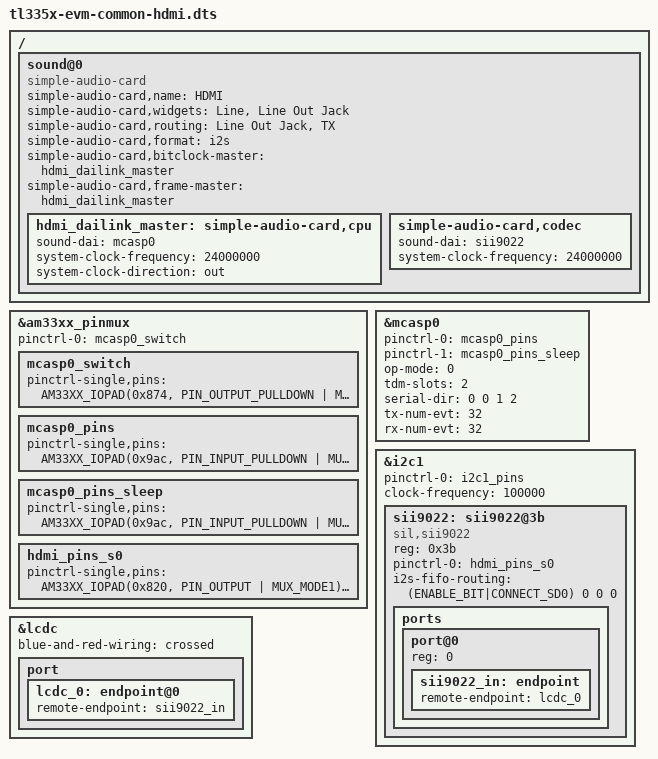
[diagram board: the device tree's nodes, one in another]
/*
 * Copyright (C) 2015 GuangZhou Tronlong co., LTD - http://www.tronlong.com
 *
 * This program is free software; you can redistribute it and/or modify
 * it under the terms of the GNU General Public License version 2 as
 * published by the Free Software Foundation.
 */

#include <dt-bindings/sound/sii9022-audio.h>
#include "tl335x-evm-common.dts"

/ {
	sound@0 {
		compatible = "simple-audio-card";
		simple-audio-card,name = "HDMI";
		simple-audio-card,widgets =
			"Line", "Line Out Jack";

		simple-audio-card,routing =
			"Line Out Jack", "TX";

		simple-audio-card,format = "i2s";
		simple-audio-card,bitclock-master = <&hdmi_dailink_master>;
		simple-audio-card,frame-master = <&hdmi_dailink_master>;
		hdmi_dailink_master: simple-audio-card,cpu {
			sound-dai = <&mcasp0>;
			/*
			* 22579200
			*/
			system-clock-frequency = <24000000>;
			system-clock-direction = "out";
		};

		simple-audio-card,codec {
			sound-dai = <&sii9022>;
			system-clock-frequency = <24000000>;
		};
	};
};

&am33xx_pinmux {
	pinctrl-0 = <&mcasp0_switch>;

	/*
	* switcher for mcasp0 signal
	* when this pin set to 0, mcasp0 signal switch to hdmi channel
	* when this pin set to 1, mcasp0 signal switch to tl3106h module
	*/
	mcasp0_switch: mcasp0_switch {
		pinctrl-single,pins = <
			AM33XX_IOPAD(0x874, PIN_OUTPUT_PULLDOWN | MUX_MODE7)	/* (U17) GPMC_WPN/GPIO0[31] */
		>;
	};

	mcasp0_pins: mcasp0_pins {
		pinctrl-single,pins = <
			AM33XX_IOPAD(0x9ac, PIN_INPUT_PULLDOWN | MUX_MODE0)	/* (A14) MCASP0_AHCLKX.MCASP0_AHCLKX */
			AM33XX_IOPAD(0x990, PIN_INPUT_PULLDOWN | MUX_MODE0)	/* (A13) MCASP0_ACLKX.MCASP0_ACLKX */
			AM33XX_IOPAD(0x994, PIN_INPUT_PULLDOWN | MUX_MODE0)	/* (B13) MCASP0_FSX.MCASP0_FSX */
			AM33XX_IOPAD(0x9a0, PIN_OUTPUT_PULLDOWN | MUX_MODE2)	/* (B12) MCASP0_ACLKR.MCASP0_AXR2 */
			AM33XX_IOPAD(0x9a4, PIN_INPUT_PULLDOWN | MUX_MODE2)	/* (C13) MCASP0_FSR.MCASP0_AXR3 */
		>;
	};

	mcasp0_pins_sleep: mcasp0_pins_sleep {
		pinctrl-single,pins = <
			AM33XX_IOPAD(0x9ac, PIN_INPUT_PULLDOWN | MUX_MODE7)
			AM33XX_IOPAD(0x990, PIN_INPUT_PULLDOWN | MUX_MODE7)
			AM33XX_IOPAD(0x994, PIN_INPUT_PULLDOWN | MUX_MODE7)
			AM33XX_IOPAD(0x9a0, PIN_INPUT_PULLDOWN | MUX_MODE7)
			AM33XX_IOPAD(0x9a4, PIN_INPUT_PULLDOWN | MUX_MODE7)
		>;
	};

	hdmi_pins_s0: hdmi_pins_s0 {
		pinctrl-single,pins = <
			AM33XX_IOPAD(0x820, PIN_OUTPUT | MUX_MODE1)		/* gpmc_ad8.lcd_data23 */
			AM33XX_IOPAD(0x824, PIN_OUTPUT | MUX_MODE1)		/* gpmc_ad9.lcd_data22 */
			AM33XX_IOPAD(0x828, PIN_OUTPUT | MUX_MODE1)		/* gpmc_ad10.lcd_data21 */
			AM33XX_IOPAD(0x82c, PIN_OUTPUT | MUX_MODE1)		/* gpmc_ad11.lcd_data20 */
			AM33XX_IOPAD(0x830, PIN_OUTPUT | MUX_MODE1)		/* gpmc_ad12.lcd_data19 */
			AM33XX_IOPAD(0x834, PIN_OUTPUT | MUX_MODE1)		/* gpmc_ad13.lcd_data18 */
			AM33XX_IOPAD(0x838, PIN_OUTPUT | MUX_MODE1)		/* gpmc_ad14.lcd_data17 */
			AM33XX_IOPAD(0x83c, PIN_OUTPUT | MUX_MODE1)		/* gpmc_ad15.lcd_data16 */
			AM33XX_IOPAD(0x8a0, PIN_OUTPUT | MUX_MODE0)		/* lcd_data0.lcd_data0 */
			AM33XX_IOPAD(0x8a4, PIN_OUTPUT | MUX_MODE0)		/* lcd_data1.lcd_data1 */
			AM33XX_IOPAD(0x8a8, PIN_OUTPUT | MUX_MODE0)		/* lcd_data2.lcd_data2 */
			AM33XX_IOPAD(0x8ac, PIN_OUTPUT | MUX_MODE0)		/* lcd_data3.lcd_data3 */
			AM33XX_IOPAD(0x8b0, PIN_OUTPUT | MUX_MODE0)		/* lcd_data4.lcd_data4 */
			AM33XX_IOPAD(0x8b4, PIN_OUTPUT | MUX_MODE0)		/* lcd_data5.lcd_data5 */
			AM33XX_IOPAD(0x8b8, PIN_OUTPUT | MUX_MODE0)		/* lcd_data6.lcd_data6 */
			AM33XX_IOPAD(0x8bc, PIN_OUTPUT | MUX_MODE0)		/* lcd_data7.lcd_data7 */
			AM33XX_IOPAD(0x8c0, PIN_OUTPUT | MUX_MODE0)		/* lcd_data8.lcd_data8 */
			AM33XX_IOPAD(0x8c4, PIN_OUTPUT | MUX_MODE0)		/* lcd_data9.lcd_data9 */
			AM33XX_IOPAD(0x8c8, PIN_OUTPUT | MUX_MODE0)		/* lcd_data10.lcd_data10 */
			AM33XX_IOPAD(0x8cc, PIN_OUTPUT | MUX_MODE0)		/* lcd_data11.lcd_data11 */
			AM33XX_IOPAD(0x8d0, PIN_OUTPUT | MUX_MODE0)		/* lcd_data12.lcd_data12 */
			AM33XX_IOPAD(0x8d4, PIN_OUTPUT | MUX_MODE0)		/* lcd_data13.lcd_data13 */
			AM33XX_IOPAD(0x8d8, PIN_OUTPUT | MUX_MODE0)		/* lcd_data14.lcd_data14 */
			AM33XX_IOPAD(0x8dc, PIN_OUTPUT | MUX_MODE0)		/* lcd_data15.lcd_data15 */
			AM33XX_IOPAD(0x8e0, PIN_OUTPUT | MUX_MODE0)		/* lcd_vsync.lcd_vsync */
			AM33XX_IOPAD(0x8e4, PIN_OUTPUT | MUX_MODE0)		/* lcd_hsync.lcd_hsync */
			AM33XX_IOPAD(0x8e8, PIN_OUTPUT | MUX_MODE0)		/* lcd_pclk.lcd_pclk */
			AM33XX_IOPAD(0x8ec, PIN_OUTPUT | MUX_MODE0)		/* lcd_ac_bias_en.lcd_ac_bias_en */
		>;
	};
};

&mcasp0 {
	#sound-dai-cells = <0>;
	pinctrl-names = "default", "sleep";
	pinctrl-0 = <&mcasp0_pins>;
	pinctrl-1 = <&mcasp0_pins_sleep>;
	status = "okay";
	op-mode = <0>;	/* MCASP_IIS_MODE */
	tdm-slots = <2>;
	/* 4 serializers */
	serial-dir = <	/* 0: INACTIVE, 1: TX, 2: RX */
		0 0 1 2
	>;
	tx-num-evt = <32>;
	rx-num-evt = <32>;
};

&i2c1 {
	pinctrl-names = "default";
	pinctrl-0 = <&i2c1_pins>;

	status = "okay";
	clock-frequency = <100000>;

	sii9022: sii9022@3b {
		#sound-dai-cells = <0>;
		compatible = "sil,sii9022";
		reg = <0x3b>;
		pinctrl-names = "default";
		pinctrl-0 = <&hdmi_pins_s0>;

		i2s-fifo-routing = <
			(ENABLE_BIT|CONNECT_SD0)
			0
			0
			0
		>;

		ports {
			#address-cells = <1>;
			#size-cells = <0>;
			port@0 {
				reg = <0>;
				sii9022_in: endpoint {
					remote-endpoint = <&lcdc_0>;
				};
			};
		};
	};
};


&lcdc {
	status = "okay";
	blue-and-red-wiring = "crossed";

	port {
		lcdc_0: endpoint@0 {
		remote-endpoint = <&sii9022_in>;
		};
	};
};
